VERSION ""
NS_ :

BS_:
BU_: Vector__XXX

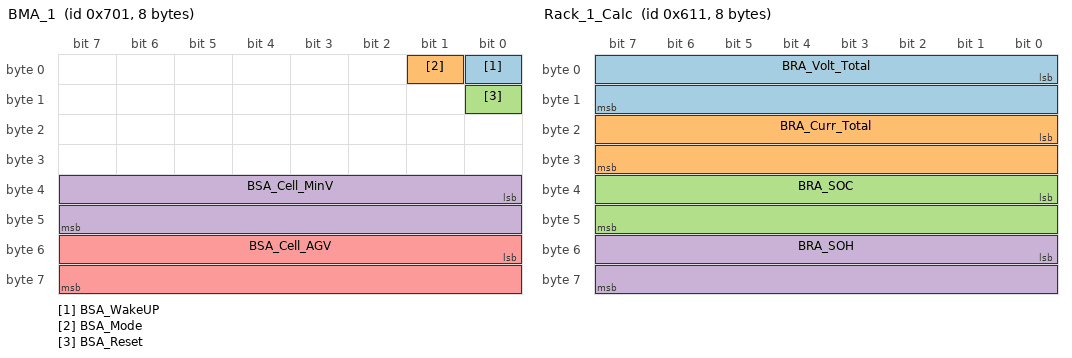
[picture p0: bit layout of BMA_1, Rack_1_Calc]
BO_ 1793 BMA_1: 8 Vector__XXX
 SG_ BSA_WakeUP : 0|1@1+ (1.0,0) [0.0|1.0] "flag" Vector__XXX
 SG_ BSA_Mode : 1|1@1+ (1.0,0) [0.0|1.0] "flag" Vector__XXX
 SG_ BSA_Reset : 8|1@1+ (1.0,0) [0.0|1.0] "flag" Vector__XXX
 SG_ BSA_Cell_MinV : 32|16@1+ (0.001,0) [2.8|4.5] "V" Vector__XXX
 SG_ BSA_Cell_AGV : 48|16@1- (0.1,0) [-40.0|100.0] "℃" Vector__XXX

BO_ 1553 Rack_1_Calc: 8 Vector__XXX
 SG_ BRA_Volt_Total : 0|16@1+ (0.1,0) [400.0|800.0] "V" Vector__XXX
 SG_ BRA_Curr_Total : 16|16@1- (0.1,0) [-500.0|500.0] "A" Vector__XXX
 SG_ BRA_SOC : 32|16@1+ (0.1,0) [0.0|120.0] "%" Vector__XXX
 SG_ BRA_SOH : 48|16@1+ (0.1,0) [0.0|100.0] "%" Vector__XXX

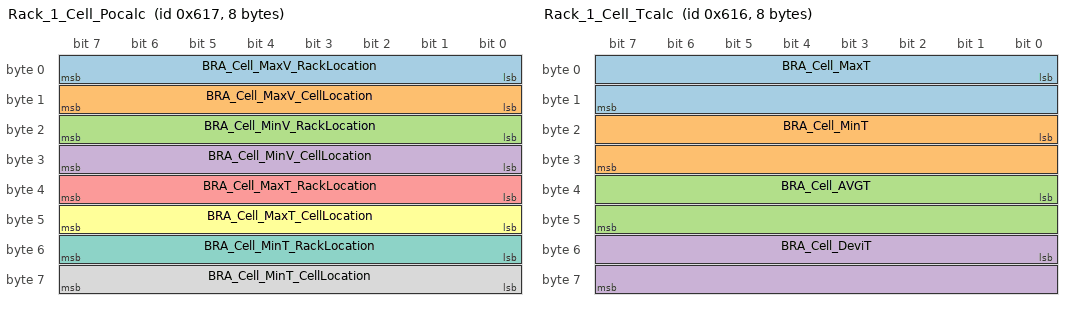
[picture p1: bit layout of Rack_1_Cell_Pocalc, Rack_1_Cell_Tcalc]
BO_ 1559 Rack_1_Cell_Pocalc: 8 Vector__XXX
 SG_ BRA_Cell_MaxV_RackLocation : 0|8@1+ (1.0,0) [1.0|4.0] "R" Vector__XXX
 SG_ BRA_Cell_MaxV_CellLocation : 8|8@1+ (1.0,0) [1.0|168.0] "C" Vector__XXX
 SG_ BRA_Cell_MinV_RackLocation : 16|8@1+ (1.0,0) [1.0|4.0] "R" Vector__XXX
 SG_ BRA_Cell_MinV_CellLocation : 24|8@1+ (1.0,0) [1.0|168.0] "C" Vector__XXX
 SG_ BRA_Cell_MaxT_RackLocation : 32|8@1+ (1.0,0) [1.0|4.0] "R" Vector__XXX
 SG_ BRA_Cell_MaxT_CellLocation : 40|8@1+ (1.0,0) [1.0|168.0] "C" Vector__XXX
 SG_ BRA_Cell_MinT_RackLocation : 48|8@1+ (1.0,0) [1.0|4.0] "R" Vector__XXX
 SG_ BRA_Cell_MinT_CellLocation : 56|8@1+ (1.0,0) [1.0|168.0] "C" Vector__XXX

BO_ 1558 Rack_1_Cell_Tcalc: 8 Vector__XXX
 SG_ BRA_Cell_MaxT : 0|16@1- (0.1,0) [-40.0|100.0] "℃" Vector__XXX
 SG_ BRA_Cell_MinT : 16|16@1- (0.1,0) [-40.0|100.0] "℃" Vector__XXX
 SG_ BRA_Cell_AVGT : 32|16@1- (0.1,0) [-40.0|100.0] "℃" Vector__XXX
 SG_ BRA_Cell_DeviT : 48|16@1+ (0.1,0) [-40.0|100.0] "℃" Vector__XXX

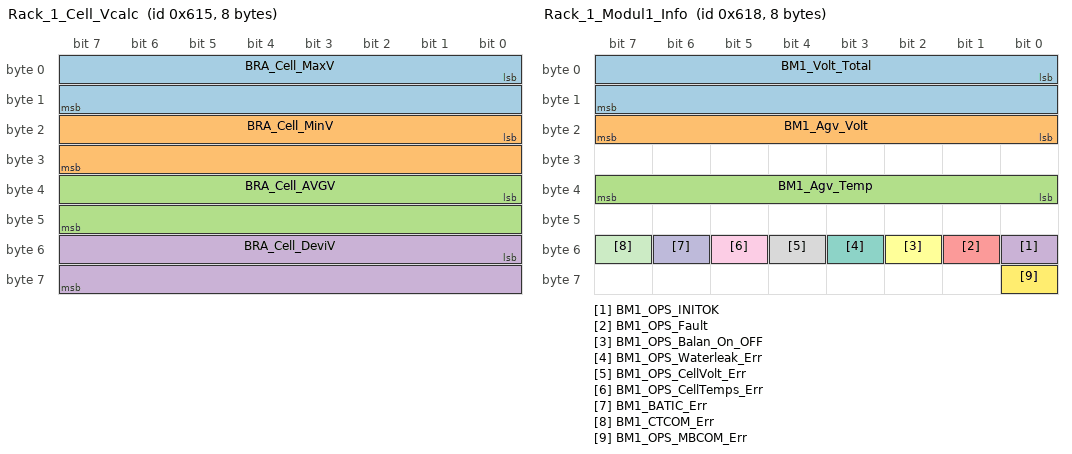
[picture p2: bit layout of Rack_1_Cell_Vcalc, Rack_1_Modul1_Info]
BO_ 1557 Rack_1_Cell_Vcalc: 8 Vector__XXX
 SG_ BRA_Cell_MaxV : 0|16@1+ (0.001,0) [2.8|4.5] "V" Vector__XXX
 SG_ BRA_Cell_MinV : 16|16@1+ (0.001,0) [2.8|4.5] "V" Vector__XXX
 SG_ BRA_Cell_AVGV : 32|16@1+ (0.001,0) [2.8|4.5] "V" Vector__XXX
 SG_ BRA_Cell_DeviV : 48|16@1+ (1.0,0) [0.0|500.0] "mV" Vector__XXX

BO_ 1560 Rack_1_Modul1_Info: 8 Vector__XXX
 SG_ BM1_Volt_Total : 0|16@1+ (0.1,0) [48.0|108.0] "V" Vector__XXX
 SG_ BM1_Agv_Volt : 16|8@1+ (0.001,0) [2.8|4.5] "V" Vector__XXX
 SG_ BM1_Agv_Temp : 32|8@1- (0.1,0) [-40.0|100.0] "℃" Vector__XXX
 SG_ BM1_OPS_INITOK : 48|1@1+ (0.0,0) [0.0|1.0] "flag" Vector__XXX
 SG_ BM1_OPS_Fault : 49|1@1+ (0.0,0) [0.0|1.0] "flag" Vector__XXX
 SG_ BM1_OPS_Balan_On_OFF : 50|1@1+ (0.0,0) [0.0|1.0] "flag" Vector__XXX
 SG_ BM1_OPS_Waterleak_Err : 51|1@1+ (0.0,0) [0.0|1.0] "flag" Vector__XXX
 SG_ BM1_OPS_CellVolt_Err : 52|1@1+ (0.0,0) [0.0|1.0] "flag" Vector__XXX
 SG_ BM1_OPS_CellTemps_Err : 53|1@1+ (0.0,0) [0.0|1.0] "flag" Vector__XXX
 SG_ BM1_BATIC_Err : 54|1@1+ (0.0,0) [0.0|1.0] "flag" Vector__XXX
 SG_ BM1_CTCOM_Err : 55|1@1+ (0.0,0) [0.0|1.0] "flag" Vector__XXX
 SG_ BM1_OPS_MBCOM_Err : 56|1@1+ (0.0,0) [0.0|1.0] "flag" Vector__XXX

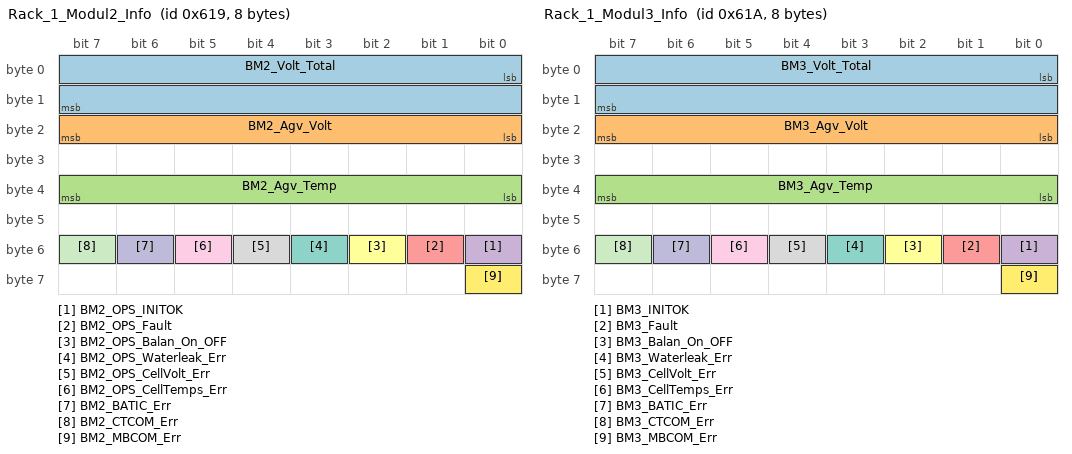
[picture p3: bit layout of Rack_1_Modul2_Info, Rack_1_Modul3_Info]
BO_ 1561 Rack_1_Modul2_Info: 8 Vector__XXX
 SG_ BM2_Volt_Total : 0|16@1+ (0.1,0) [48.0|108.0] "V" Vector__XXX
 SG_ BM2_Agv_Volt : 16|8@1+ (0.001,0) [2.8|4.5] "V" Vector__XXX
 SG_ BM2_Agv_Temp : 32|8@1- (0.1,0) [-40.0|100.0] "℃" Vector__XXX
 SG_ BM2_OPS_INITOK : 48|1@1+ (0.0,0) [0.0|1.0] "flag" Vector__XXX
 SG_ BM2_OPS_Fault : 49|1@1+ (0.0,0) [0.0|1.0] "flag" Vector__XXX
 SG_ BM2_OPS_Balan_On_OFF : 50|1@1+ (0.0,0) [0.0|1.0] "flag" Vector__XXX
 SG_ BM2_OPS_Waterleak_Err : 51|1@1+ (0.0,0) [0.0|1.0] "flag" Vector__XXX
 SG_ BM2_OPS_CellVolt_Err : 52|1@1+ (0.0,0) [0.0|1.0] "flag" Vector__XXX
 SG_ BM2_OPS_CellTemps_Err : 53|1@1+ (0.0,0) [0.0|1.0] "flag" Vector__XXX
 SG_ BM2_BATIC_Err : 54|1@1+ (0.0,0) [0.0|1.0] "flag" Vector__XXX
 SG_ BM2_CTCOM_Err : 55|1@1+ (0.0,0) [0.0|1.0] "flag" Vector__XXX
 SG_ BM2_MBCOM_Err : 56|1@1+ (0.0,0) [0.0|1.0] "flag" Vector__XXX

BO_ 1562 Rack_1_Modul3_Info: 8 Vector__XXX
 SG_ BM3_Volt_Total : 0|16@1+ (0.1,0) [48.0|108.0] "V" Vector__XXX
 SG_ BM3_Agv_Volt : 16|8@1+ (0.001,0) [2.8|4.5] "V" Vector__XXX
 SG_ BM3_Agv_Temp : 32|8@1- (0.1,0) [-40.0|100.0] "℃" Vector__XXX
 SG_ BM3_INITOK : 48|1@1+ (0.0,0) [0.0|1.0] "flag" Vector__XXX
 SG_ BM3_Fault : 49|1@1+ (0.0,0) [0.0|1.0] "flag" Vector__XXX
 SG_ BM3_Balan_On_OFF : 50|1@1+ (0.0,0) [0.0|1.0] "flag" Vector__XXX
 SG_ BM3_Waterleak_Err : 51|1@1+ (0.0,0) [0.0|1.0] "flag" Vector__XXX
 SG_ BM3_CellVolt_Err : 52|1@1+ (0.0,0) [0.0|1.0] "flag" Vector__XXX
 SG_ BM3_CellTemps_Err : 53|1@1+ (0.0,0) [0.0|1.0] "flag" Vector__XXX
 SG_ BM3_BATIC_Err : 54|1@1+ (0.0,0) [0.0|1.0] "flag" Vector__XXX
 SG_ BM3_CTCOM_Err : 55|1@1+ (0.0,0) [0.0|1.0] "flag" Vector__XXX
 SG_ BM3_MBCOM_Err : 56|1@1+ (0.0,0) [0.0|1.0] "flag" Vector__XXX

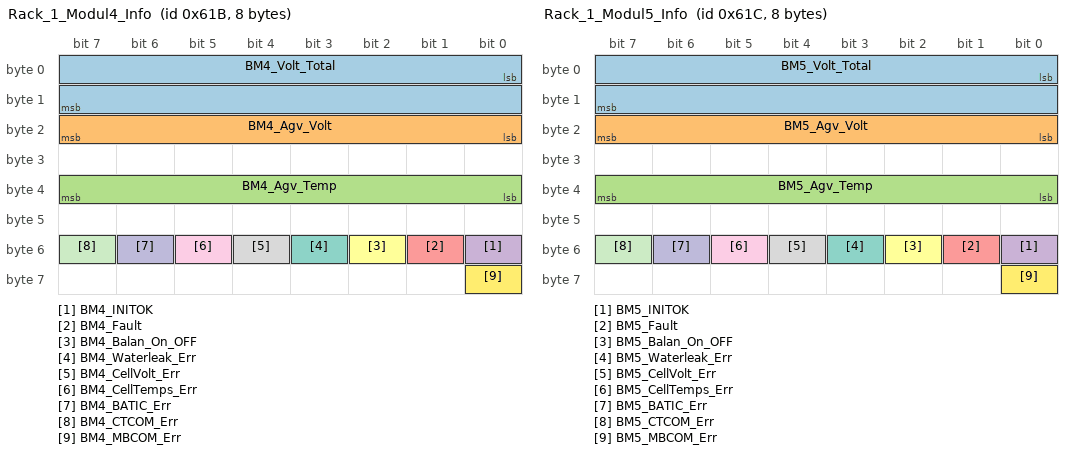
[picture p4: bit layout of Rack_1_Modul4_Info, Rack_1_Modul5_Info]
BO_ 1563 Rack_1_Modul4_Info: 8 Vector__XXX
 SG_ BM4_Volt_Total : 0|16@1+ (0.1,0) [48.0|108.0] "V" Vector__XXX
 SG_ BM4_Agv_Volt : 16|8@1+ (0.001,0) [2.8|4.5] "V" Vector__XXX
 SG_ BM4_Agv_Temp : 32|8@1- (0.1,0) [-40.0|100.0] "℃" Vector__XXX
 SG_ BM4_INITOK : 48|1@1+ (0.0,0) [0.0|1.0] "flag" Vector__XXX
 SG_ BM4_Fault : 49|1@1+ (0.0,0) [0.0|1.0] "flag" Vector__XXX
 SG_ BM4_Balan_On_OFF : 50|1@1+ (0.0,0) [0.0|1.0] "flag" Vector__XXX
 SG_ BM4_Waterleak_Err : 51|1@1+ (0.0,0) [0.0|1.0] "flag" Vector__XXX
 SG_ BM4_CellVolt_Err : 52|1@1+ (0.0,0) [0.0|1.0] "flag" Vector__XXX
 SG_ BM4_CellTemps_Err : 53|1@1+ (0.0,0) [0.0|1.0] "flag" Vector__XXX
 SG_ BM4_BATIC_Err : 54|1@1+ (0.0,0) [0.0|1.0] "flag" Vector__XXX
 SG_ BM4_CTCOM_Err : 55|1@1+ (0.0,0) [0.0|1.0] "flag" Vector__XXX
 SG_ BM4_MBCOM_Err : 56|1@1+ (0.0,0) [0.0|1.0] "flag" Vector__XXX

BO_ 1564 Rack_1_Modul5_Info: 8 Vector__XXX
 SG_ BM5_Volt_Total : 0|16@1+ (0.1,0) [48.0|108.0] "V" Vector__XXX
 SG_ BM5_Agv_Volt : 16|8@1+ (0.001,0) [2.8|4.5] "V" Vector__XXX
 SG_ BM5_Agv_Temp : 32|8@1- (0.1,0) [-40.0|100.0] "℃" Vector__XXX
 SG_ BM5_INITOK : 48|1@1+ (0.0,0) [0.0|1.0] "flag" Vector__XXX
 SG_ BM5_Fault : 49|1@1+ (0.0,0) [0.0|1.0] "flag" Vector__XXX
 SG_ BM5_Balan_On_OFF : 50|1@1+ (0.0,0) [0.0|1.0] "flag" Vector__XXX
 SG_ BM5_Waterleak_Err : 51|1@1+ (0.0,0) [0.0|1.0] "flag" Vector__XXX
 SG_ BM5_CellVolt_Err : 52|1@1+ (0.0,0) [0.0|1.0] "flag" Vector__XXX
 SG_ BM5_CellTemps_Err : 53|1@1+ (0.0,0) [0.0|1.0] "flag" Vector__XXX
 SG_ BM5_BATIC_Err : 54|1@1+ (0.0,0) [0.0|1.0] "flag" Vector__XXX
 SG_ BM5_CTCOM_Err : 55|1@1+ (0.0,0) [0.0|1.0] "flag" Vector__XXX
 SG_ BM5_MBCOM_Err : 56|1@1+ (0.0,0) [0.0|1.0] "flag" Vector__XXX

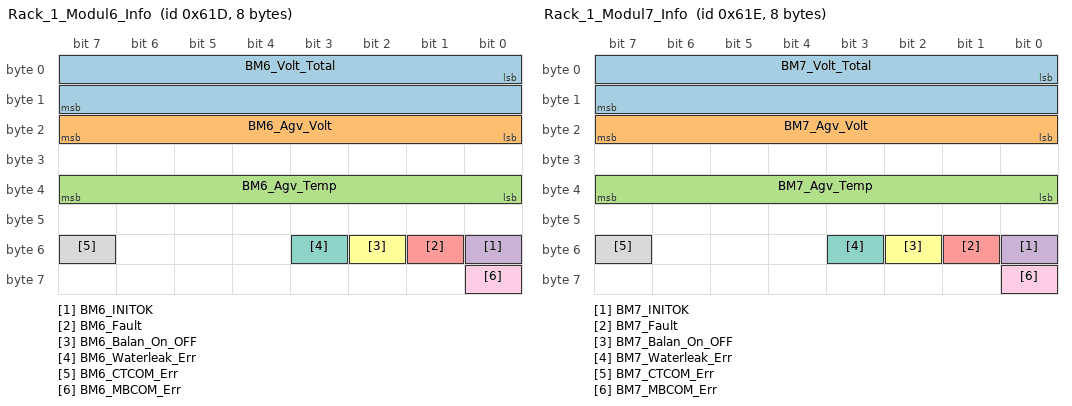
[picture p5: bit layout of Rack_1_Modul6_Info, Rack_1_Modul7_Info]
BO_ 1565 Rack_1_Modul6_Info: 8 Vector__XXX
 SG_ BM6_Volt_Total : 0|16@1+ (0.1,0) [48.0|108.0] "V" Vector__XXX
 SG_ BM6_Agv_Volt : 16|8@1+ (0.001,0) [2.8|4.5] "V" Vector__XXX
 SG_ BM6_Agv_Temp : 32|8@1- (0.1,0) [-40.0|100.0] "℃" Vector__XXX
 SG_ BM6_INITOK : 48|1@1+ (0.0,0) [0.0|1.0] "flag" Vector__XXX
 SG_ BM6_Fault : 49|1@1+ (0.0,0) [0.0|1.0] "flag" Vector__XXX
 SG_ BM6_Balan_On_OFF : 50|1@1+ (0.0,0) [0.0|1.0] "flag" Vector__XXX
 SG_ BM6_Waterleak_Err : 51|1@1+ (0.0,0) [0.0|1.0] "flag" Vector__XXX
 SG_ BM6_CTCOM_Err : 55|1@1+ (0.0,0) [0.0|1.0] "flag" Vector__XXX
 SG_ BM6_MBCOM_Err : 56|1@1+ (0.0,0) [0.0|1.0] "flag" Vector__XXX

BO_ 1566 Rack_1_Modul7_Info: 8 Vector__XXX
 SG_ BM7_Volt_Total : 0|16@1+ (0.1,0) [48.0|108.0] "V" Vector__XXX
 SG_ BM7_Agv_Volt : 16|8@1+ (0.001,0) [2.8|4.5] "V" Vector__XXX
 SG_ BM7_Agv_Temp : 32|8@1- (0.1,0) [-40.0|100.0] "℃" Vector__XXX
 SG_ BM7_INITOK : 48|1@1+ (0.0,0) [0.0|1.0] "flag" Vector__XXX
 SG_ BM7_Fault : 49|1@1+ (0.0,0) [0.0|1.0] "flag" Vector__XXX
 SG_ BM7_Balan_On_OFF : 50|1@1+ (0.0,0) [0.0|1.0] "flag" Vector__XXX
 SG_ BM7_Waterleak_Err : 51|1@1+ (0.0,0) [0.0|1.0] "flag" Vector__XXX
 SG_ BM7_CTCOM_Err : 55|1@1+ (0.0,0) [0.0|1.0] "flag" Vector__XXX
 SG_ BM7_MBCOM_Err : 56|1@1+ (0.0,0) [0.0|1.0] "flag" Vector__XXX

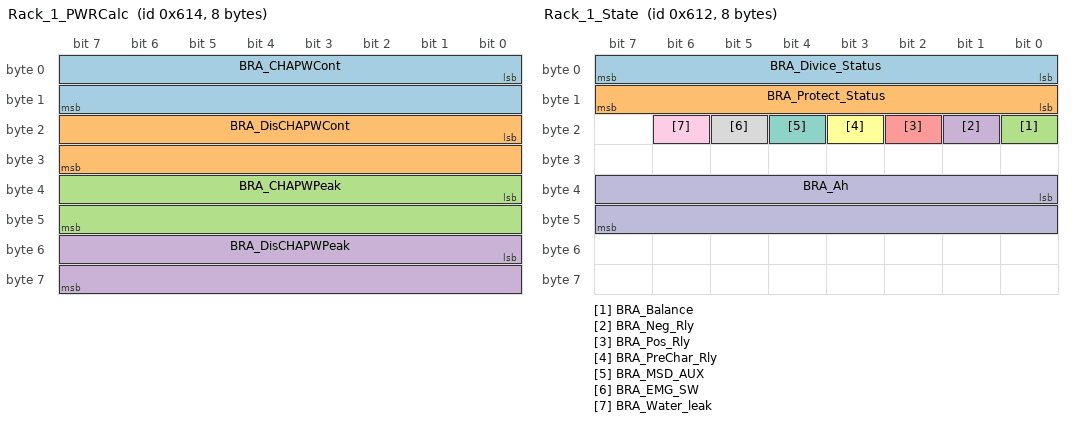
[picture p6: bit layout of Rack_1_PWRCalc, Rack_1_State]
BO_ 1556 Rack_1_PWRCalc: 8 Vector__XXX
 SG_ BRA_CHAPWCont : 0|16@1+ (0.1,0) [0.0|43.0] "kw" Vector__XXX
 SG_ BRA_DisCHAPWCont : 16|16@1+ (0.1,0) [0.0|100.0] "kw" Vector__XXX
 SG_ BRA_CHAPWPeak : 32|16@1+ (0.1,0) [0.0|60.0] "kW" Vector__XXX
 SG_ BRA_DisCHAPWPeak : 48|16@1+ (0.1,0) [0.0|200.0] "kW" Vector__XXX

BO_ 1555 Rack_1_ProtectState: 8 Vector__XXX
 SG_ BRA_Wn_Dischager_OC : 0|1@1+ (1.0,0) [0.0|1.0] "flag" Vector__XXX
 SG_ BRA_Wn_Chager_OC : 1|1@1+ (1.0,0) [0.0|1.0] "flag" Vector__XXX
 SG_ BRA_Wn_SOC_OV : 2|1@1+ (1.0,0) [0.0|1.0] "flag" Vector__XXX
 SG_ BRA_Wn_SOC_Un : 3|1@1+ (1.0,0) [0.0|1.0] "flag" Vector__XXX
 SG_ BRA_Wn_OV : 4|1@1+ (1.0,0) [0.0|1.0] "flag" Vector__XXX
 SG_ BRA_Wn_UV : 5|1@1+ (1.0,0) [0.0|1.0] "flag" Vector__XXX
 SG_ BRA_Wn_Cell_OV : 6|1@1+ (1.0,0) [0.0|1.0] "flag" Vector__XXX
 SG_ BRA_Wn_Cell_UV : 7|1@1+ (1.0,0) [0.0|1.0] "flag" Vector__XXX
 SG_ BRA_Wn_Cell_UnbalV : 8|1@1+ (1.0,0) [0.0|1.0] "flag" Vector__XXX
 SG_ BRA_Wn_DisCharger_Cell_OT : 9|1@1+ (1.0,0) [0.0|1.0] "flag" Vector__XXX
 SG_ BRA_Wn_Charger_Cell_OT : 10|1@1+ (1.0,0) [0.0|1.0] "flag" Vector__XXX
 SG_ BRA_Wn_DisCharger_Cell_UT : 11|1@1+ (1.0,0) [0.0|1.0] "flag" Vector__XXX
 SG_ BRA_Wn_Charger_Cell_UT : 12|1@1+ (1.0,0) [0.0|1.0] "flag" Vector__XXX
 SG_ BRA_Wn_Cell_UnbalT : 13|1@1+ (1.0,0) [0.0|1.0] "flag" Vector__XXX
 SG_ BRA_Wn_Discharger_UnbaPWR : 14|1@1+ (1.0,0) [0.0|1.0] "flag" Vector__XXX
 SG_ BRA_Wn_Charger_UnbaPWR : 15|1@1+ (1.0,0) [0.0|1.0] "flag" Vector__XXX
 SG_ BRA_FLT_Dischager_OC : 16|1@1+ (1.0,0) [0.0|1.0] "flag" Vector__XXX
 SG_ BRA_FLT_Chager_OC : 17|1@1+ (1.0,0) [0.0|1.0] "flag" Vector__XXX
 SG_ BRA_FLT_SOC_OV : 18|1@1+ (1.0,0) [0.0|1.0] "flag" Vector__XXX
 SG_ BRA_FLT_SOC_Un : 19|1@1+ (1.0,0) [0.0|1.0] "flag" Vector__XXX
 SG_ BRA_FLT_OV : 20|1@1+ (1.0,0) [0.0|1.0] "flag" Vector__XXX
 SG_ BRA_FLT_UV : 21|1@1+ (1.0,0) [0.0|1.0] "flag" Vector__XXX
 SG_ BRA_FLT_Cell_OV : 22|1@1+ (1.0,0) [0.0|1.0] "flag" Vector__XXX
 SG_ BRA_FLT_Cell_UV : 23|1@1+ (1.0,0) [0.0|1.0] "flag" Vector__XXX
 SG_ BRA_FLT_Cell_UnbalV : 24|1@1+ (1.0,0) [0.0|1.0] "flag" Vector__XXX
 SG_ BRA_FLT_DisCharger_Cell_OT : 25|1@1+ (1.0,0) [0.0|1.0] "flag" Vector__XXX
 SG_ BRA_FLT_Charger_Cell_OT : 26|1@1+ (1.0,0) [0.0|1.0] "flag" Vector__XXX
 SG_ BRA_FLT_DisCharger_Cell_UT : 27|1@1+ (1.0,0) [0.0|1.0] "flag" Vector__XXX
 SG_ BRA_FLT_Charger_Cell_UT : 28|1@1+ (1.0,0) [0.0|1.0] "flag" Vector__XXX
 SG_ BRA_FLT_Cell_UnbalT : 29|1@1+ (1.0,0) [0.0|1.0] "flag" Vector__XXX
 SG_ BRA_FLT_Discharger_UnbaPWR : 30|1@1+ (1.0,0) [0.0|1.0] "flag" Vector__XXX
 SG_ BRA_FLT_Charger_UnbaPWR : 31|1@1+ (1.0,0) [0.0|1.0] "flag" Vector__XXX
 SG_ BRA_Prtct_Dischager_OC : 32|1@1+ (1.0,0) [0.0|1.0] "flag" Vector__XXX
 SG_ BRA_Prtct_Chager_OC : 33|1@1+ (1.0,0) [0.0|1.0] "flag" Vector__XXX
 SG_ BRA_Prtct_SOC_OV : 34|1@1+ (1.0,0) [0.0|1.0] "flag" Vector__XXX
 SG_ BRA_Prtct_SOC_Un : 35|1@1+ (1.0,0) [0.0|1.0] "flag" Vector__XXX
 SG_ BRA_Prtct_OV : 36|1@1+ (1.0,0) [0.0|1.0] "flag" Vector__XXX
 SG_ BRA_Prtct_UV : 37|1@1+ (1.0,0) [0.0|1.0] "flag" Vector__XXX
 SG_ BRA_Prtct_Cell_OV : 38|1@1+ (1.0,0) [0.0|1.0] "flag" Vector__XXX
 SG_ BRA_Prtct_Cell_UV : 39|1@1+ (1.0,0) [0.0|1.0] "flag" Vector__XXX
 SG_ BRA_Prtct_Cell_UnbalV : 40|1@1+ (1.0,0) [0.0|1.0] "flag" Vector__XXX
 SG_ BRA_Prtct_DisCharger_Cell_OT : 41|1@1+ (1.0,0) [0.0|1.0] "flag" Vector__XXX
 SG_ BRA_Prtct_Charger_Cell_OT : 42|1@1+ (1.0,0) [0.0|1.0] "flag" Vector__XXX
 SG_ BRA_Prtct_DisCharger_Cell_UT : 43|1@1+ (1.0,0) [0.0|1.0] "flag" Vector__XXX
 SG_ BRA_Prtct_Charger_Cell_UT : 44|1@1+ (1.0,0) [0.0|1.0] "flag" Vector__XXX
 SG_ BRA_Prtct_Cell_UnbalT : 45|1@1+ (1.0,0) [0.0|1.0] "flag" Vector__XXX
 SG_ BRA_Prtct_Discharger_UnbaPWR : 46|1@1+ (1.0,0) [0.0|1.0] "flag" Vector__XXX
 SG_ BRA_Prtct_Charger_UnbaPWR : 47|1@1+ (1.0,0) [0.0|1.0] "flag" Vector__XXX
 SG_ BRA_Prtct_Rly_Err : 48|1@1+ (1.0,0) [0.0|1.0] "flag" Vector__XXX
 SG_ BRA_Prtct_IN_COM_Err : 49|1@1+ (1.0,0) [0.0|1.0] "flag" Vector__XXX
 SG_ BRA_Prtct_EX_COM_Err : 50|1@1+ (1.0,0) [0.0|1.0] "flag" Vector__XXX
 SG_ BRA_Prtct_CT_COM_Err : 51|1@1+ (1.0,0) [0.0|1.0] "flag" Vector__XXX
 SG_ BRA_Prtct_Water_Leak_Err : 52|1@1+ (1.0,0) [0.0|1.0] "flag" Vector__XXX
 SG_ BRA_Prtct_EMS_SW_Err : 53|1@1+ (1.0,0) [0.0|1.0] "flag" Vector__XXX

BO_ 1554 Rack_1_State: 8 Vector__XXX
 SG_ BRA_Divice_Status : 0|8@1+ (1.0,0) [0.0|4.0] "State" Vector__XXX
 SG_ BRA_Protect_Status : 8|8@1+ (1.0,0) [0.0|4.0] "State" Vector__XXX
 SG_ BRA_Balance : 16|1@1+ (1.0,0) [0.0|1.0] "flag" Vector__XXX
 SG_ BRA_Neg_Rly : 17|1@1+ (1.0,0) [0.0|1.0] "flag" Vector__XXX
 SG_ BRA_Pos_Rly : 18|1@1+ (1.0,0) [0.0|1.0] "flag" Vector__XXX
 SG_ BRA_PreChar_Rly : 19|1@1+ (1.0,0) [0.0|1.0] "flag" Vector__XXX
 SG_ BRA_MSD_AUX : 20|1@1+ (1.0,0) [0.0|1.0] "flag" Vector__XXX
 SG_ BRA_EMG_SW : 21|1@1+ (1.0,0) [0.0|1.0] "flag" Vector__XXX
 SG_ BRA_Water_leak : 22|1@1+ (1.0,0) [0.0|1.0] "flag" Vector__XXX
 SG_ BRA_Ah : 32|16@1- (1.0,0) [-100.0|-100.0] "Ah" Vector__XXX

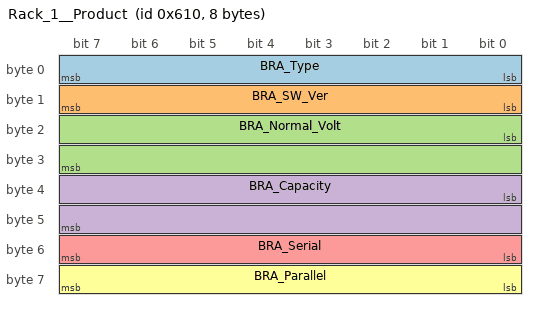
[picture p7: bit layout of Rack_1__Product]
BO_ 1552 Rack_1__Product: 8 Vector__XXX
 SG_ BRA_Type : 0|8@1+ (1.0,0) [0.0|10.0] "Ty" Vector__XXX
 SG_ BRA_SW_Ver : 8|8@1+ (0.1,0) [1.0|2.55] "VER" Vector__XXX
 SG_ BRA_Normal_Volt : 16|16@1+ (0.1,0) [400.0|800.0] "V" Vector__XXX
 SG_ BRA_Capacity : 32|16@1+ (0.1,0) [30.0|500.0] "Ah" Vector__XXX
 SG_ BRA_Serial : 48|8@1+ (1.0,0) [0.0|200.0] "S" Vector__XXX
 SG_ BRA_Parallel : 56|8@1+ (1.0,0) [0.0|10.0] "P" Vector__XXX
